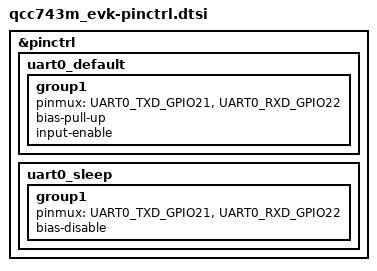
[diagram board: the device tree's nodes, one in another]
/*
 * Copyright (c) 2026 Qualcomm Technologies, Inc. and/or its subsidiaries
 * SPDX-License-Identifier: Apache-2.0
 */

&pinctrl {
	uart0_default: uart0_default {
		group1 {
			pinmux = <UART0_TXD_GPIO21>,
				 <UART0_RXD_GPIO22>;
			bias-pull-up;
			input-enable;
		};
	};

	uart0_sleep: uart0_sleep {
		group1 {
			pinmux = <UART0_TXD_GPIO21>,
				 <UART0_RXD_GPIO22>;
			bias-disable;
		};
	};
};
